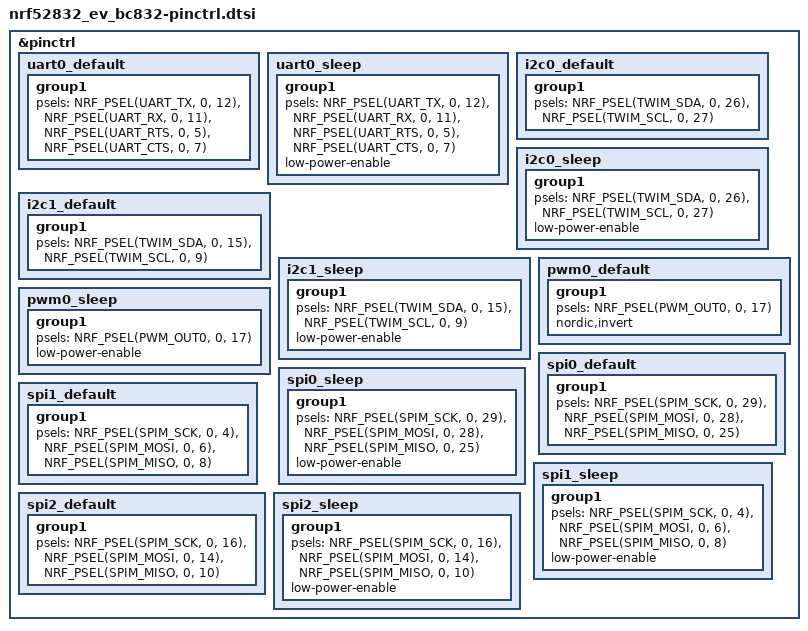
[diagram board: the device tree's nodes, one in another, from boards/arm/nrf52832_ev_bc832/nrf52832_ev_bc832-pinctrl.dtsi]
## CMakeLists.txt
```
# SPDX-License-Identifier: Apache-2.0

cmake_minimum_required(VERSION 3.20.0)
find_package(Zephyr REQUIRED HINTS $ENV{ZEPHYR_BASE})
project(littlefs)

target_sources(app PRIVATE 
    src/main.c
    src/mx25l51245g_flash.c
    LittleFS/lfs.c
    LittleFS/lfs_util.c
)

# Add include directories
target_include_directories(app PRIVATE
    LittleFS
    src
)

# Configure LittleFS with basic settings
target_compile_definitions(app PRIVATE
    LFS_NO_DEBUG
    LFS_NO_WARN
    LFS_NO_ERROR
)
```

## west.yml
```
/*
 * west.yml - West manifest for dependencies
 */

manifest:
  self:
    path: littleFS

  remotes:
    - name: zephyrproject-rtos
      url-base: https://github.com/zephyrproject-rtos

  projects:
    - name: zephyr
      remote: zephyrproject-rtos
      revision: main
      import:
        # By using name-allowlist we can clone only the modules that are
        # strictly needed by the application.
        name-allowlist:
          - cmsis      # required by the ARM port
          - hal_nordic # required by the nrf52832 SoC
          - mbedtls    # required by the nrf_security module
```

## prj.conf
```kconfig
# Enable SPI
CONFIG_SPI=y

# Basic SPI configuration
CONFIG_SPI_ASYNC=y

# Enable GPIO
CONFIG_GPIO=y
CONFIG_GPIO_AS_PINRESET=n

# Make sure printk is printing to the UART console
CONFIG_CONSOLE=y

# Disable Zephyr's built-in LittleFS since we're using local LittleFS
CONFIG_FILE_SYSTEM=n
CONFIG_FILE_SYSTEM_MKFS=n
CONFIG_FILE_SYSTEM_LITTLEFS=n

# Disable Zephyr flash subsystem since we're using custom driver
CONFIG_FLASH=n
CONFIG_FLASH_MAP=n
CONFIG_FLASH_PAGE_LAYOUT=n

CONFIG_FPU=y
CONFIG_CBPRINTF_FP_SUPPORT=y

# Enable RTT
CONFIG_USE_SEGGER_RTT=y
CONFIG_RTT_CONSOLE=y
CONFIG_UART_CONSOLE=n

# Enable logging
CONFIG_LOG=y
CONFIG_LOG_BACKEND_RTT=y
CONFIG_LOG_PRINTK=y
CONFIG_LOG_DEFAULT_LEVEL=3

# Reduce debug noise
CONFIG_SPI_LOG_LEVEL_WRN=y

# Larger RTT Buffer to handle all messages
CONFIG_SEGGER_RTT_BUFFER_SIZE_UP=4096

# Enable system initialization

# Memory configuration - Increased for LittleFS
CONFIG_MAIN_STACK_SIZE=8192
CONFIG_HEAP_MEM_POOL_SIZE=32768
CONFIG_SYSTEM_WORKQUEUE_STACK_SIZE=4096

# Enable time functions for struct tm
CONFIG_NEWLIB_LIBC=y
CONFIG_NEWLIB_LIBC_FLOAT_PRINTF=y

# Allow SPIM driver on nRF52832 despite Product Anomaly 58
CONFIG_SOC_NRF52832_ALLOW_SPIM_DESPITE_PAN_58=y

# Clock configuration - Force 64MHz HFCLK
CONFIG_CLOCK_CONTROL=y
CONFIG_CLOCK_CONTROL_NRF=y
CONFIG_CLOCK_CONTROL_NRF_K32SRC_RC=y
CONFIG_SYS_CLOCK_HW_CYCLES_PER_SEC=64000000
```

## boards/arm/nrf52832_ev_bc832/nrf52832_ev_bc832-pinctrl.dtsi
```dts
/*
 * Copyright (c) 2022 Nordic Semiconductor
 * SPDX-License-Identifier: Apache-2.0
 */

&pinctrl {
	uart0_default: uart0_default {
		group1 {
			psels = <NRF_PSEL(UART_TX, 0, 12)>,
				<NRF_PSEL(UART_RX, 0, 11)>,
				<NRF_PSEL(UART_RTS, 0, 5)>,
				<NRF_PSEL(UART_CTS, 0, 7)>;
		};
	};

	uart0_sleep: uart0_sleep {
		group1 {
			psels = <NRF_PSEL(UART_TX, 0, 12)>,
				<NRF_PSEL(UART_RX, 0, 11)>,
				<NRF_PSEL(UART_RTS, 0, 5)>,
				<NRF_PSEL(UART_CTS, 0, 7)>;
			low-power-enable;
		};
	};

	i2c0_default: i2c0_default {
		group1 {
			psels = <NRF_PSEL(TWIM_SDA, 0, 26)>,
				<NRF_PSEL(TWIM_SCL, 0, 27)>;
		};
	};

	i2c0_sleep: i2c0_sleep {
		group1 {
			psels = <NRF_PSEL(TWIM_SDA, 0, 26)>,
				<NRF_PSEL(TWIM_SCL, 0, 27)>;
			low-power-enable;
		};
	};

	i2c1_default: i2c1_default {
		group1 {
			psels = <NRF_PSEL(TWIM_SDA, 0, 15)>,
				<NRF_PSEL(TWIM_SCL, 0, 9)>;
		};
	};

	i2c1_sleep: i2c1_sleep {
		group1 {
			psels = <NRF_PSEL(TWIM_SDA, 0, 15)>,
				<NRF_PSEL(TWIM_SCL, 0, 9)>;
			low-power-enable;
		};
	};

	pwm0_default: pwm0_default {
		group1 {
			psels = <NRF_PSEL(PWM_OUT0, 0, 17)>;
			nordic,invert;
		};
	};

	pwm0_sleep: pwm0_sleep {
		group1 {
			psels = <NRF_PSEL(PWM_OUT0, 0, 17)>;
			low-power-enable;
		};
	};

	spi0_default: spi0_default {
		group1 {
			psels = <NRF_PSEL(SPIM_SCK, 0, 29)>,
				<NRF_PSEL(SPIM_MOSI, 0, 28)>,
				<NRF_PSEL(SPIM_MISO, 0, 25)>;
		};
	};

	spi0_sleep: spi0_sleep {
		group1 {
			psels = <NRF_PSEL(SPIM_SCK, 0, 29)>,
				<NRF_PSEL(SPIM_MOSI, 0, 28)>,
				<NRF_PSEL(SPIM_MISO, 0, 25)>;
			low-power-enable;
		};
	};

	spi1_default: spi1_default {
		group1 {
			psels = <NRF_PSEL(SPIM_SCK, 0, 4)>,
				<NRF_PSEL(SPIM_MOSI, 0, 6)>,
				<NRF_PSEL(SPIM_MISO, 0, 8)>;
		};
	};

	spi1_sleep: spi1_sleep {
		group1 {
			psels = <NRF_PSEL(SPIM_SCK, 0, 4)>,
				<NRF_PSEL(SPIM_MOSI, 0, 6)>,
				<NRF_PSEL(SPIM_MISO, 0, 8)>;
			low-power-enable;
		};
	};

	spi2_default: spi2_default {
		group1 {
			psels = <NRF_PSEL(SPIM_SCK, 0, 16)>,
				<NRF_PSEL(SPIM_MOSI, 0, 14)>,
				<NRF_PSEL(SPIM_MISO, 0, 10)>;
		};
	};

	spi2_sleep: spi2_sleep {
		group1 {
			psels = <NRF_PSEL(SPIM_SCK, 0, 16)>,
				<NRF_PSEL(SPIM_MOSI, 0, 14)>,
				<NRF_PSEL(SPIM_MISO, 0, 10)>;
			low-power-enable;
		};
	};

};
```

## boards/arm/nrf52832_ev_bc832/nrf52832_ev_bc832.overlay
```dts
/*
 * Device Tree Overlay for Macronix MX25L51245GZ2I-08G NOR Flash
 * boards/nrf52832_ev_bc832.overlay
 */

&pinctrl {
	spi0_flash: spi0_flash {
		group1 {
			psels = <NRF_PSEL(SPIM_SCK, 0, 25)>,
				<NRF_PSEL(SPIM_MOSI, 0, 23)>,
				<NRF_PSEL(SPIM_MISO, 0, 24)>;
		};
	};

	spi0_flash_sleep: spi0_flash_sleep {
		group1 {
			psels = <NRF_PSEL(SPIM_SCK, 0, 25)>,
				<NRF_PSEL(SPIM_MOSI, 0, 23)>,
				<NRF_PSEL(SPIM_MISO, 0, 24)>;
			low-power-enable;
		};
	};
};

&clock {
	hfclk-frequency = <64000000>;
};

&spi0 {
    compatible = "nordic,nrf-spim";
	status = "okay";
	pinctrl-0 = <&spi0_flash>;
	pinctrl-1 = <&spi0_flash_sleep>;
	pinctrl-names = "default", "sleep";

    cs-gpios = <&gpio0 22 GPIO_ACTIVE_LOW>;
};
```

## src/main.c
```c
/*
 * Copyright (c) 2016 Intel Corporation
 *
 * SPDX-License-Identifier: Apache-2.0
 * Note:
 * Tested on nRF Connect SDK Version : 2.0
 */

#include <zephyr/kernel.h>
#include <zephyr/device.h>
#include <zephyr/devicetree.h>
#include <zephyr/drivers/gpio.h>
#include <zephyr/logging/log.h>
#include <string.h>
#include <time.h>
#include <errno.h>
#include "mx25l51245g_flash.h"
#include <zephyr/drivers/clock_control.h>
#include <zephyr/drivers/clock_control/nrf_clock_control.h>


/* STEP 9 - Increase the sleep time from 100ms to 10 minutes  */
#define SLEEP_TIME_MS 10 * 60 * 1000

/* SW0_NODE is the devicetree node identifier for the node with alias "sw0" */
#define SW0_NODE DT_ALIAS(sw0)
#define SW1_NODE DT_ALIAS(sw1)
#define SW2_NODE DT_ALIAS(sw2)
#define SW3_NODE DT_ALIAS(sw3)
static const struct gpio_dt_spec button0 = GPIO_DT_SPEC_GET(SW0_NODE, gpios);
static const struct gpio_dt_spec button1 = GPIO_DT_SPEC_GET(SW1_NODE, gpios);
static const struct gpio_dt_spec button2 = GPIO_DT_SPEC_GET(SW2_NODE, gpios);
static const struct gpio_dt_spec button3 = GPIO_DT_SPEC_GET(SW3_NODE, gpios);

/* LED0_NODE is the devicetree node identifier for the node with alias "led0". */
#define LED0_NODE DT_ALIAS(led0)
#define LED1_NODE DT_ALIAS(led1)
#define LED2_NODE DT_ALIAS(led2)
#define LED3_NODE DT_ALIAS(led3)
static const struct gpio_dt_spec led0 = GPIO_DT_SPEC_GET(LED0_NODE, gpios);
static const struct gpio_dt_spec led1 = GPIO_DT_SPEC_GET(LED1_NODE, gpios);
static const struct gpio_dt_spec led2 = GPIO_DT_SPEC_GET(LED2_NODE, gpios);
static const struct gpio_dt_spec led3 = GPIO_DT_SPEC_GET(LED3_NODE, gpios);

/* STEP 4 - Define the callback function */
void button0_pressed(const struct device *dev, struct gpio_callback *cb, uint32_t pins)
{
	gpio_pin_toggle_dt(&led0);
}
void button1_pressed(const struct device *dev, struct gpio_callback *cb, uint32_t pins)
{
	gpio_pin_toggle_dt(&led1);
}
void button2_pressed(const struct device *dev, struct gpio_callback *cb, uint32_t pins)
{
	gpio_pin_toggle_dt(&led2);
}
void button3_pressed(const struct device *dev, struct gpio_callback *cb, uint32_t pins)
{
	gpio_pin_toggle_dt(&led3);
}
/* STEP 5 - Define a variable of type static struct gpio_callback */
static struct gpio_callback button0_cb_data;
static struct gpio_callback button1_cb_data;
static struct gpio_callback button2_cb_data;
static struct gpio_callback button3_cb_data;


LOG_MODULE_REGISTER(main, LOG_LEVEL_DBG);

/* Data structure for setup.bin file */
typedef struct {
    int id;
    char name[20];
    float temperature_c;
    struct tm setDateTime;
} MyData;


int main(void)
{
	int ret;

	if (!device_is_ready(led0.port)) {
		return -1;
	}
	if (!device_is_ready(led1.port)) {
		return -1;
	}
	if (!device_is_ready(led2.port)) {
		return -1;
	}
	if (!device_is_ready(led3.port)) {
		return -1;
	}

	if (!device_is_ready(button0.port)) {
		return -1;
	}
	if (!device_is_ready(button1.port)) {
		return -1;
	}
	if (!device_is_ready(button2.port)) {
		return -1;
	}
	if (!device_is_ready(button3.port)) {
		return -1;
	}

	ret = gpio_pin_configure_dt(&led0, GPIO_OUTPUT_INACTIVE);
	if (ret < 0) {
		return -1;
	}
	ret = gpio_pin_configure_dt(&led1, GPIO_OUTPUT_INACTIVE);
	if (ret < 0) {
		return -1;
	}
	ret = gpio_pin_configure_dt(&led2, GPIO_OUTPUT_INACTIVE);
	if (ret < 0) {
		return -1;
	}
	ret = gpio_pin_configure_dt(&led3, GPIO_OUTPUT_INACTIVE);
	if (ret < 0) {
		return -1;
	}


	ret = gpio_pin_configure_dt(&button0, GPIO_INPUT);
	if (ret < 0) {
		return -1;
	}
	ret = gpio_pin_configure_dt(&button1, GPIO_INPUT);
	if (ret < 0) {
		return -1;
	}
	ret = gpio_pin_configure_dt(&button2, GPIO_INPUT);
	if (ret < 0) {
		return -1;
	}
	ret = gpio_pin_configure_dt(&button3, GPIO_INPUT);
	if (ret < 0) {
		return -1;
	}
	/* STEP 3 - Configure the interrupt on the button's pin */
	ret = gpio_pin_interrupt_configure_dt(&button0, GPIO_INT_EDGE_TO_ACTIVE);
	ret = gpio_pin_interrupt_configure_dt(&button1, GPIO_INT_EDGE_TO_ACTIVE);
	ret = gpio_pin_interrupt_configure_dt(&button2, GPIO_INT_EDGE_TO_ACTIVE);
	ret = gpio_pin_interrupt_configure_dt(&button3, GPIO_INT_EDGE_TO_ACTIVE);

	/* STEP 6 - Initialize the static struct gpio_callback variable   */
	gpio_init_callback(&button0_cb_data, button0_pressed, BIT(button0.pin));
	gpio_init_callback(&button1_cb_data, button1_pressed, BIT(button1.pin));
	gpio_init_callback(&button2_cb_data, button2_pressed, BIT(button2.pin));
	gpio_init_callback(&button3_cb_data, button3_pressed, BIT(button3.pin));

	/* STEP 7 - Add the callback function by calling gpio_add_callback()   */
	gpio_add_callback(button0.port, &button0_cb_data);
	gpio_add_callback(button1.port, &button1_cb_data);
	gpio_add_callback(button2.port, &button2_cb_data);
	gpio_add_callback(button3.port, &button3_cb_data);


	// ******************** Little FS test **************



	char write_data[] = "Hello, MX25L51245G NOR Flash with LittleFS!";
    	char read_buffer[100];
    
    	LOG_INF("Starting MX25L51245G NOR Flash Demo");
    
    // Check actual CPU frequency
    uint32_t cpu_freq = sys_clock_hw_cycles_per_sec();
    LOG_INF("CPU running at %u Hz (%u MHz)", cpu_freq, cpu_freq / 1000000);
    
    // Initialize the system
    // Initialize the full system with LittleFS
    ret = mx25l51245g_system_init();
    if (ret != 0) {
        LOG_ERR("System initialization failed");
        return ret;
    }
    
    // Write test file
    ret = mx25l51245g_write_file("test.txt", write_data, strlen(write_data));
    if (ret != 0) {
        LOG_ERR("Write test failed");
        return ret;
    }
    
    // Read test file
    memset(read_buffer, 0, sizeof(read_buffer));
    ret = mx25l51245g_read_file("test.txt", read_buffer, sizeof(read_buffer));
    if (ret < 0) {
        LOG_ERR("Read test failed");
        return ret;
    }
    
    LOG_INF("Read data: %s", read_buffer);
    
    // Verify data
    if (strcmp(write_data, read_buffer) == 0) {
        LOG_INF("Data verification successful!");
    } else {
        LOG_ERR("Data verification failed!");
    }
    
    // ******************** Setup.bin struct test **************
    
    LOG_INF("Reading setup.bin file...");
    
    MyData readData;
    static char dateTimeStr[128];
    
    // Direct read of setup.bin file
    ret = mx25l51245g_read_struct("setup.bin", &readData, sizeof(MyData));
    
    if (ret == -ENOENT) {
        LOG_INF("setup.bin file does not exist");
    } else if (ret < 0) {
        LOG_ERR("Failed to read setup.bin file: error %d", ret);
    } else {
        // Successfully read the file - display the data
        strftime(dateTimeStr, sizeof(dateTimeStr), "%Y-%m-%d %H:%M:%SZ", &readData.setDateTime);
        
        LOG_INF("Setup Data Read Successfully:");
        LOG_INF("  ID: %d", readData.id);
        LOG_INF("  Name: %s", readData.name);
        LOG_INF("  Temperature: %.1f°C", (double)readData.temperature_c);
        LOG_INF("  Date/Time: %s", dateTimeStr);
    }

	// ******************** schedule.sch struct test **************

	struct tm newTime = {
		.tm_year = 2025 - 1900U,
		.tm_mon = 9 - 1U,
		.tm_mday = 5U,
		.tm_hour = 15U,
		.tm_min = 30U,
		.tm_sec = 0U
	};	

	MyData writeData = {2,"struct from nRF", 21.0, newTime};

   
    LOG_INF("Writing setup2.bin file...");    
   
	ret = mx25l51245g_write_struct("setup2.bin", &writeData, sizeof(MyData));

    ret = mx25l51245g_read_struct("setup2.bin", &readData, sizeof(MyData));
    
    if (ret == -ENOENT) {
        LOG_INF("setup2.bin file does not exist");
    } else if (ret < 0) {
        LOG_ERR("Failed to read setup2.bin file: error %d", ret);
    } else {
        // Successfully read the file - display the data
        strftime(dateTimeStr, sizeof(dateTimeStr), "%Y-%m-%d %H:%M:%SZ", &readData.setDateTime);
        
        LOG_INF("Setup2.bin Data Read Successfully:");
        LOG_INF("  ID: %d", readData.id);
        LOG_INF("  Name: %s", readData.name);
        LOG_INF("  Temperature(°C): %.1f", (double)readData.temperature_c);
        LOG_INF("  Date/Time: %s", dateTimeStr);
    }

	//***************************************************	

	while (1) {
		/* STEP 8 - Remove the polling code */

		k_msleep(SLEEP_TIME_MS);
	}
}
```

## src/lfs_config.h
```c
/*
 * LittleFS Configuration for Embedded Zephyr Application
 */

#ifndef LFS_CONFIG_H
#define LFS_CONFIG_H

#include <zephyr/kernel.h>
#include <zephyr/logging/log.h>

// Use Zephyr's logging instead of printf
#define LFS_NO_DEBUG
#define LFS_NO_WARN
#define LFS_NO_ERROR

// Use Zephyr's assertion
#define LFS_ASSERT(test) __ASSERT(test, "LFS assertion failed")

// Use Zephyr's memory functions for dynamic allocation
#define LFS_MALLOC(size) k_malloc(size)
#define LFS_FREE(ptr) k_free(ptr)

// Thread safety - use Zephyr mutexes if needed
// For now, assume single-threaded access
#define LFS_THREADSAFE 0

#endif /* LFS_CONFIG_H */
```

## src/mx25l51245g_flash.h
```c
/*
 * MX25L51245GZ2I-08G NOR Flash Driver with LittleFS Support
 * Header File
 */

#ifndef MX25L51245G_FLASH_H
#define MX25L51245G_FLASH_H

#include <zephyr/kernel.h>

#ifdef __cplusplus
extern "C" {
#endif

/* Public API Functions */
int mx25l51245g_system_init(void);
int mx25l51245g_basic_init(void);
int mx25l51245g_basic_test(void);
int mx25l51245g_write_file(const char *filename, const void *data, size_t len);
int mx25l51245g_read_file(const char *filename, void *buffer, size_t len);
int mx25l51245g_write_struct(const char *filename, const void *data, size_t size);
int mx25l51245g_read_struct(const char *filename, void *buffer, size_t size);

#ifdef __cplusplus
}
#endif

#endif /* MX25L51245G_FLASH_H */
```
